# rpi3b register map
Vendor: Raspberr Pi Foundation; Series: raspberry pi; File version: 0.1
CPU: CA53 r3p0, little endian, MPU, FPU, I-cache, D-cache, 0 interrupt priority bits
Registers are 32-bit, access not given, no defined reset value unless marked. A register's access mark holds for its fields unless they carry their own. Offsets are from the block's base; [hi:lo] are bit positions.

## ArmTimer — This is the timer that is on the arm chip. This is *not* the system timer peripheral. The arm-side timer is document in chapter 14 of the BCM2835 manual, whereas the system timer is documented in chapter 12. The qemu emulator does not have the match registers for the system timer. The arm-side timer requires care to use on real hardware, as it is tied to the system clock, whose speed can vary because of low-power modes. You need to either check the clock speed or configure it in your config.txt to have a stable value. This description has been updated to reflect the errors documented in the errata on pages 197 and 198.
Base ?
0x00 Load rw — Timer Load Register. The timer load register sets the time for the timer to count down. This value is loaded into the timer value register after the load register has been written or if the timer-value register has counted down to 0.
0x04 Value ro — Timer Value Register. This register holds the current timer value and is counted down when the counter is running. It is counted down each timer clock until the value 0 is reached. Then the value register is re-loaded from the timer load register and the interrupt pending bit is set. The timer count down speed is set by the timer pre-divide register.
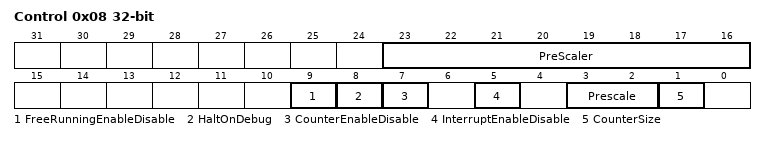
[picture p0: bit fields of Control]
0x08 Control rw — Timer Control Register. The standard SP804 timer control register consist of 8 bits but in the BCM implementation there are more control bits for the extra features. Control bits 0-7 are identical to the SP804 bits, albeit some functionality of the SP804 is not implemented. All new control bits start from bit 8 upwards.
  [23:16] PreScaler — Free running counter pre-scaler. Freq is sys_clk/(prescale+1)
  [9] FreeRunningEnableDisable — 0 : Free running counter Disabled 1 : Free running counter Enabled
  [8] HaltOnDebug — 0 : Timers keeps running if ARM is in debug halted mode 1 : Timers halted if ARM is in debug halted mode
  [7] CounterEnableDisable — 0 : Timer disabled 1 : Timer enabled
  [5] InterruptEnableDisable — 0 : Timer Interrupt disabled 1 : Timer Interrupt enabled
  [3:2] Prescale — 00 : pre-scale is clock / 1 (No pre-scale) 01 : pre-scale is clock / 16 10 : pre-scale is clock / 256 11 : pre-scale is clock / 1 (Undefined in 804)
    0=NoPreScale (prescale is clock/1); 1=prescale is clock/16; 2=prescale is clock/256
  [1] CounterSize — 0 : 16-bit counters 1 : 32-bit counter
    0=SixteenBit; 1=ThirtyTwoBit
0x0C IRQClear wo — The timer IRQ clear register is write only. When writing this register the interrupt-pending bit is cleared. When reading this register it returns 0x544D5241 which is the ASCII reversed value for "ARMT".
0x10 RawIRQStatus ro — It shows the status of the interrupt pending bit.
  [0] Pending
0x14 MaskedIRQStatus ro — The masked IRQ register is a read-only register. It shows the status of the interrupt signal. It is simply a logical AND of the interrupt pending bit and the interrupt enable bit.
  [0] Asserted
0x18 Reload rw — This register is a copy of the timer load register. The difference is that a write to this register does not trigger an immediate reload of the timer value register. Instead the timer load register value is only accessed if the value register has finished counting down to zero.
0x1C PreDivide rw — The Pre-divider register is not present in the SP804. Compensates for the lack of a 1Mhz clock.
  [9:0] Value — The pre-divider register is 10 bits wide and can be written or read from. This register has been added as the SP804 expects a 1MHz clock which we do not have. Instead the pre-divider takes the APB clock and divides it down according to: timer_clock = apb_clock/(pre_divider+1) The reset value of this register is 0x7D so gives a divide by 126.
0x20 Counter ro — The free running counter is not present in the SP804. The free running counter is a 32 bits wide read only register. The register is enabled by setting bit 9 of the Timer control register. The free running counter is incremented immediately after it is enabled. The timer can not be reset but when enabled, will always increment and roll-over. The free running counter is also running from the APB clock and has its own clock pre-divider controlled by bits 16-23 of the timer control register. This register will be halted too if bit 8 of the control register is set and the ARM is in Debug Halt mode.
